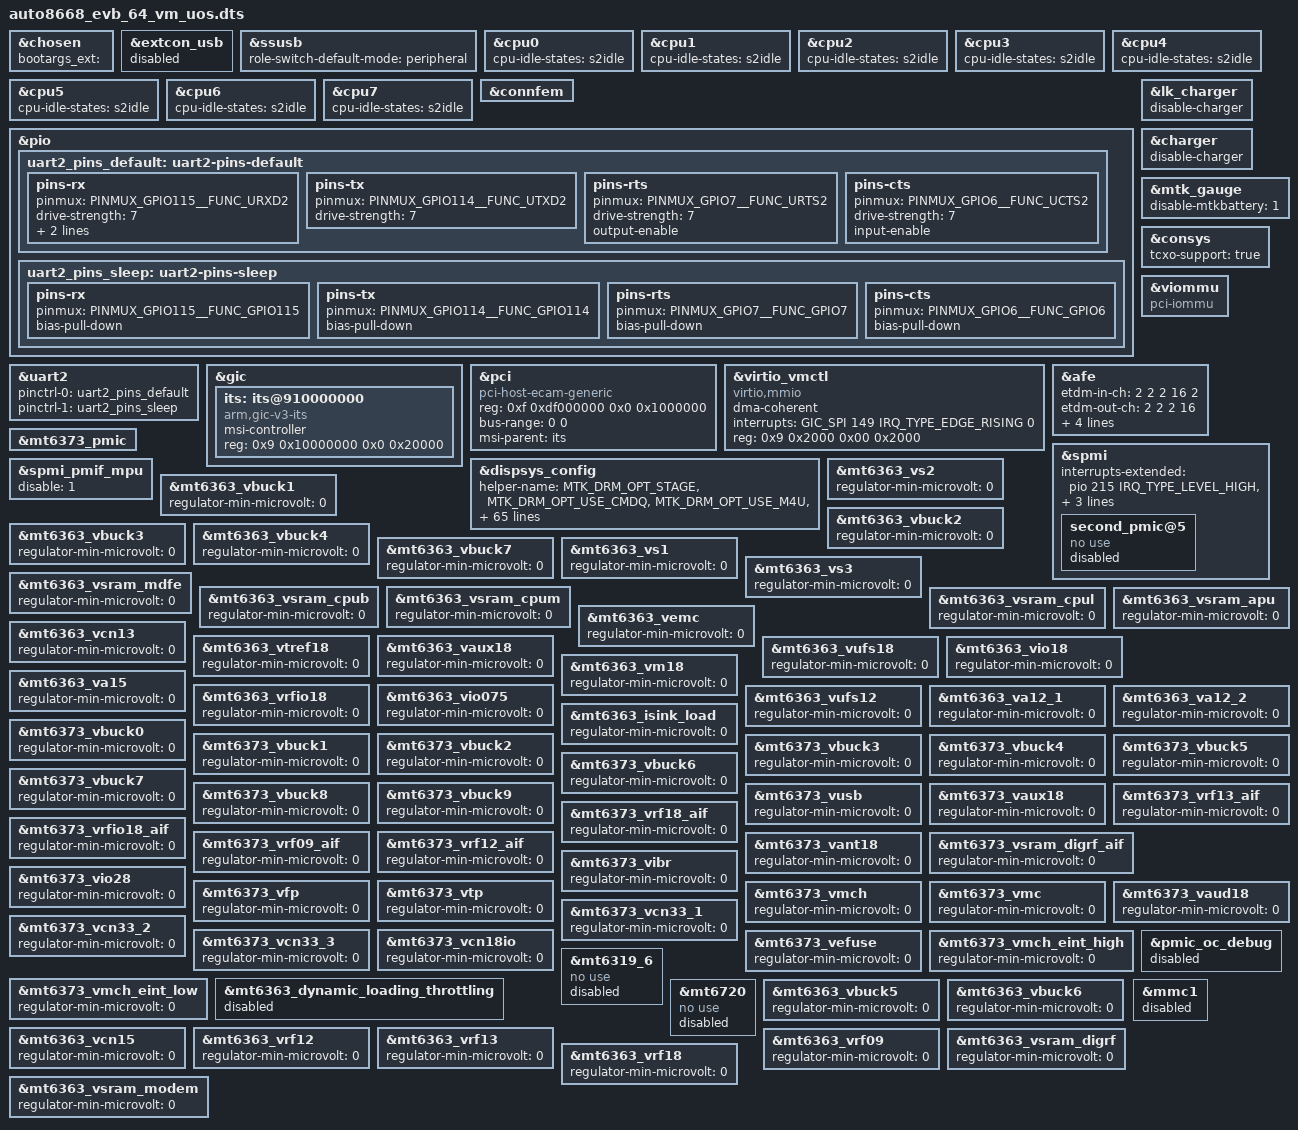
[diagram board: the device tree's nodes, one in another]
// SPDX-License-Identifier: (GPL-2.0 OR MIT)
/*
 * Copyright (c) 2024 MediaTek Inc.
 */

/dts-v1/;
/plugin/;
#include <dt-bindings/interrupt-controller/arm-gic.h>
#include <dt-bindings/interrupt-controller/irq.h>
#include <dt-bindings/pinctrl/mt6881-pinfunc.h>
#include <dt-bindings/phy/phy.h>

/* chosen */
&chosen {
	bootargs_ext = "";
};

&extcon_usb{
	status = "disabled";
};

&ssusb {
	vusb33-supply = <&mt6373_vusb>;
	role-switch-default-mode = "peripheral";
};

&cpu0 {
	cpu-idle-states = <&s2idle>;
};

&cpu1 {
	cpu-idle-states = <&s2idle>;
};

&cpu2 {
	cpu-idle-states = <&s2idle>;
};

&cpu3 {
	cpu-idle-states = <&s2idle>;
};

&cpu4 {
	cpu-idle-states = <&s2idle>;
};

&cpu5 {
	cpu-idle-states = <&s2idle>;
};

&cpu6 {
	cpu-idle-states = <&s2idle>;
};

&cpu7 {
	cpu-idle-states = <&s2idle>;
};

&extcon_usb{
	status = "disabled";
};

&ssusb {
	/delete-property/ vusb33-supply;
	/delete-node/ port;
};

&connfem {
/* Enable epa_elna node to support Wifi & BT ePA/eLNA FEM on customer load */
#if 0
	epa-elna {
		parts = <&wlan7207h &wlan7207c>;
		wifi {
			flags-0 {
				open-loop;
			};
		};
		bt {
			flags-0 {
				/* choose one of: epa-elna/epa/elna/bypass */
				epa-elna;
			};
		};
	};
#endif
};

&pio {
	uart2_pins_default: uart2-pins-default {
		pins-rx {
			pinmux = <PINMUX_GPIO115__FUNC_URXD2>;
			drive-strength = <7>;
			input-enable;
			bias-pull-up;
		};
		pins-tx {
			pinmux = <PINMUX_GPIO114__FUNC_UTXD2>;
			drive-strength = <7>;
		};
		pins-rts {
			pinmux = <PINMUX_GPIO7__FUNC_URTS2>;
			drive-strength = <7>;
			output-enable;
		};
		pins-cts {
			pinmux = <PINMUX_GPIO6__FUNC_UCTS2>;
			drive-strength = <7>;
			input-enable;
		};
	};

	uart2_pins_sleep: uart2-pins-sleep {
		pins-rx {
			pinmux = <PINMUX_GPIO115__FUNC_GPIO115>;
			bias-pull-down;
		};
		pins-tx {
			pinmux = <PINMUX_GPIO114__FUNC_GPIO114>;
			bias-pull-down;
		};
		pins-rts {
			pinmux = <PINMUX_GPIO7__FUNC_GPIO7>;
			bias-pull-down;
		};
		pins-cts {
			pinmux = <PINMUX_GPIO6__FUNC_GPIO6>;
			bias-pull-down;
		};
	};
};


&uart2 {
	pinctrl-names = "default", "sleep";
	pinctrl-0 = <&uart2_pins_default>;
	pinctrl-1 = <&uart2_pins_sleep>;
	status = "okay";
};

&lk_charger {
	disable-charger;
};

&charger {
	disable-charger;
};

&mtk_gauge {
	disable-mtkbattery = <1>;
};

/* CONNSYS TCXO GPIO start */
&consys {
	tcxo-support = "true";
};

&gic {
	ranges;
	its: its@910000000 {
		compatible = "arm,gic-v3-its";
		msi-controller;
		reg = <0x9 0x10000000 0x0 0x20000>;
	};
};

// virtio-pci bus is used to enumerate virtio devices
&pci {
	device_type = "pci";
	compatible = "pci-host-ecam-generic";
	status = "okay";
	reg = <0xf 0xdf000000 0x0 0x1000000>;
	bus-range = <0 0>;
	ranges = <0x2000000 0x0 0xe0001000 0xf 0xe0001000 0x0 0xffff000>;
	#address-cells = <3>;
	#size-cells = <2>;
	#interrupt-cells = <1>;
	msi-parent = <&its>;
};

&virtio_vmctl {
	dma-coherent;
	status = "okay";
	/* must be in sync with mmio irq in uos_alps_pv8678.lua */
	interrupts = <GIC_SPI 149 IRQ_TYPE_EDGE_RISING 0>;
	reg = <0x9 0x2000 0x00 0x2000>;
	compatible = "virtio,mmio";
};

&viommu {
	compatible = "pci-iommu";
	#iommu-cells = <1>;
	status = "okay";
};

&afe {
	etdm-in-ch = <2 2 2 16 2>;
	etdm-out-ch = <2 2 2 16>;
	etdm-in-format = <0 0 0 4 0>;
	etdm-out-format = <0 0 0 4>;
	etdmin6-clk-always-on = <0xf 0xbb80 0x80 0x20 0x10>;/* ao_level, lrck, mclk_ratio, bck_width, channels */
};

&dispsys_config {
	helper-name = "MTK_DRM_OPT_STAGE",
		"MTK_DRM_OPT_USE_CMDQ",
		"MTK_DRM_OPT_USE_M4U",
		"MTK_DRM_OPT_MMQOS_SUPPORT",
		"MTK_DRM_OPT_MMDVFS_SUPPORT",
		"MTK_DRM_OPT_SODI_SUPPORT",
		"MTK_DRM_OPT_IDLE_MGR",
		"MTK_DRM_OPT_IDLEMGR_SWTCH_DECOUPLE",
		"MTK_DRM_OPT_IDLEMGR_BY_REPAINT",
		"MTK_DRM_OPT_IDLEMGR_ENTER_ULPS",
		"MTK_DRM_OPT_IDLEMGR_KEEP_LP11",
		"MTK_DRM_OPT_DYNAMIC_RDMA_GOLDEN_SETTING",
		"MTK_DRM_OPT_IDLEMGR_DISABLE_ROUTINE_IRQ",
		"MTK_DRM_OPT_IDLEMGR_ASYNC",
		"MTK_DRM_OPT_MET_LOG",
		"MTK_DRM_OPT_USE_PQ",
		"MTK_DRM_OPT_ESD_CHECK_RECOVERY",
		"MTK_DRM_OPT_ESD_CHECK_SWITCH",
		"MTK_DRM_OPT_PRESENT_FENCE",
		"MTK_DRM_OPT_RDMA_UNDERFLOW_AEE",
		"MTK_DRM_OPT_DSI_UNDERRUN_AEE",
		"MTK_DRM_OPT_ODDMR_OD_AEE",
		"MTK_DRM_OPT_ODDMR_DMR_AEE",
		"MTK_DRM_OPT_HRT",
		"MTK_DRM_OPT_HRT_MODE",
		"MTK_DRM_OPT_DELAYED_TRIGGER",
		"MTK_DRM_OPT_OVL_EXT_LAYER",
		"MTK_DRM_OPT_AOD",
		"MTK_DRM_OPT_RPO",
		"MTK_DRM_OPT_DUAL_PIPE",
		"MTK_DRM_OPT_DC_BY_HRT",
		"MTK_DRM_OPT_OVL_WCG",
		"MTK_DRM_OPT_OVL_SBCH",
		"MTK_DRM_OPT_COMMIT_NO_WAIT_VBLANK",
		"MTK_DRM_OPT_MET",
		"MTK_DRM_OPT_REG_PARSER_RAW_DUMP",
		"MTK_DRM_OPT_VP_PQ",
		"MTK_DRM_OPT_GAME_PQ",
		"MTK_DRM_OPT_MMPATH",
		"MTK_DRM_OPT_HBM",
		"MTK_DRM_OPT_VDS_PATH_SWITCH",
		"MTK_DRM_OPT_LAYER_REC",
		"MTK_DRM_OPT_CLEAR_LAYER",
		"MTK_DRM_OPT_LFR",
		"MTK_DRM_OPT_SF_PF",
		"MTK_DRM_OPT_DYN_MIPI_CHANGE",
		"MTK_DRM_OPT_PRIM_DUAL_PIPE",
		"MTK_DRM_OPT_MSYNC2_0",
		"MTK_DRM_OPT_MML_PRIMARY",
		"MTK_DRM_OPT_MML_SUPPORT_CMD_MODE",
		"MTK_DRM_OPT_MML_PQ",
		"MTK_DRM_OPT_MML_IR",
		"MTK_DRM_OPT_DUAL_TE",
		"MTK_DRM_OPT_RES_SWITCH",
		"MTK_DRM_OPT_PREFETCH_TE",
		"MTK_DRM_OPT_DPC_EN",
		"MTK_DRM_OPT_VIDLE_TOP_EN",
		"MTK_DRM_OPT_VIDLE_APSRC_OFF",
		"MTK_DRM_OPT_VIDLE_DSI_PLL_OFF",
		"MTK_DRM_OPT_VIDLE_VDO_PANEL",
		"MTK_DRM_OPT_VIDLE_HOME_SCREEN_IDLE",
		"MTK_DRM_OPT_VIDLE_FULL_SCENARIO",
		"MTK_DRM_OPT_DPC_PRE_TE_EN",
		"MTK_DRM_OPT_MMDVFS_MODE_SWITCH",
		"MTK_DRM_OPT_CHECK_TRIGGER_MERGE",
		"MTK_DRM_OPT_VIRTUAL_DISP",
		"MTK_DRM_OPT_OVL_BW_MONITOR",
		"MTK_DRM_OPT_GPU_CACHE",
		"MTK_DRM_OPT_SPHRT",
		"MTK_DRM_OPT_SDPA_OVL_SWITCH",
		"MTK_DRM_OPT_HRT_BY_LARB",
		"MTK_DRM_OPT_MAX_CHANNEL_HRT",
		"MTK_DRM_OPT_RES_SWITCH_ON_AP",
		"MTK_DRM_OPT_TILE_OVERHEAD";

	helper-value = <0>, /*MTK_DRM_OPT_STAGE*/
		<1>, /*MTK_DRM_OPT_USE_CMDQ*/
		<1>, /*MTK_DRM_OPT_USE_M4U*/
		<0>, /*MTK_DRM_OPT_MMQOS_SUPPORT*/
		<0>, /*MTK_DRM_OPT_MMDVFS_SUPPORT*/
		<0>, /*MTK_DRM_OPT_SODI_SUPPORT*/
		<0>, /*MTK_DRM_OPT_IDLE_MGR*/
		<0>, /*MTK_DRM_OPT_IDLEMGR_SWTCH_DECOUPLE*/
		<0>, /*MTK_DRM_OPT_IDLEMGR_BY_REPAINT*/
		<0>, /*MTK_DRM_OPT_IDLEMGR_ENTER_ULPS*/
		<0>, /*MTK_DRM_OPT_IDLEMGR_KEEP_LP11*/
		<0>, /*MTK_DRM_OPT_DYNAMIC_RDMA_GOLDEN_SETTING*/
		<0>, /*MTK_DRM_OPT_IDLEMGR_DISABLE_ROUTINE_IRQ*/
		<0>, /*MTK_DRM_OPT_IDLEMGR_ASYNC*/
		<0>, /*MTK_DRM_OPT_MET_LOG*/
		<0>, /*MTK_DRM_OPT_USE_PQ*/
		<0>, /*MTK_DRM_OPT_ESD_CHECK_RECOVERY*/
		<0>, /*MTK_DRM_OPT_ESD_CHECK_SWITCH*/
		<1>, /*MTK_DRM_OPT_PRESENT_FENCE*/
		<0>, /*MTK_DRM_OPT_RDMA_UNDERFLOW_AEE*/
		<0>, /*MTK_DRM_OPT_DSI_UNDERRUN_AEE*/
		<0>, /*MTK_DRM_OPT_ODDMR_OD_AEE*/
		<0>, /*MTK_DRM_OPT_ODDMR_DMR_AEE*/
		<1>, /*MTK_DRM_OPT_HRT*/
		<0>, /*MTK_DRM_OPT_HRT_MODE*/
		<0>, /*MTK_DRM_OPT_DELAYED_TRIGGER*/
		<1>, /*MTK_DRM_OPT_OVL_EXT_LAYER*/
		<0>, /*MTK_DRM_OPT_AOD*/
		<0>, /*MTK_DRM_OPT_RPO*/
		<0>, /*MTK_DRM_OPT_DUAL_PIPE*/
		<0>, /*MTK_DRM_OPT_DC_BY_HRT*/
		<0>, /*MTK_DRM_OPT_OVL_WCG*/
		<0>, /*MTK_DRM_OPT_OVL_SBCH*/
		<1>, /*MTK_DRM_OPT_COMMIT_NO_WAIT_VBLANK*/
		<0>, /*MTK_DRM_OPT_MET*/
		<0>, /*MTK_DRM_OPT_REG_PARSER_RAW_DUMP*/
		<0>, /*MTK_DRM_OPT_VP_PQ*/
		<0>, /*MTK_DRM_OPT_GAME_PQ*/
		<0>, /*MTK_DRM_OPT_MMPATH*/
		<0>, /*MTK_DRM_OPT_HBM*/
		<0>, /*MTK_DRM_OPT_VDS_PATH_SWITCH*/
		<0>, /*MTK_DRM_OPT_LAYER_REC*/
		<1>, /*MTK_DRM_OPT_CLEAR_LAYER*/
		<0>, /*MTK_DRM_OPT_LFR*/
		<0>, /*MTK_DRM_OPT_SF_PF*/
		<1>, /*MTK_DRM_OPT_DYN_MIPI_CHANGE*/
		<0>, /*MTK_DRM_OPT_PRIM_DUAL_PIPE*/
		<0>, /*MTK_DRM_OPT_MSYNC2_0*/
		<0>, /*MTK_DRM_OPT_MML_PRIMARY*/
		<0>, /*MTK_DRM_OPT_MML_SUPPORT_CMD_MODE*/
		<0>, /*MTK_DRM_OPT_MML_PQ*/
		<0>, /*MTK_DRM_OPT_MML_IR*/
		<0>, /*MTK_DRM_OPT_DUAL_TE*/
		<0>, /*MTK_DRM_OPT_RES_SWITCH*/
		<0>, /*MTK_DRM_OPT_PREFETCH_TE*/
		<1>, /*MTK_DRM_OPT_DPC_EN*/
		<0>, /*MTK_DRM_OPT_VIDLE_TOP_EN*/
		<0>, /*MTK_DRM_OPT_VIDLE_APSRC_OFF*/
		<0>, /*MTK_DRM_OPT_VIDLE_DSI_PLL_OFF*/
		<0>, /*MTK_DRM_OPT_VIDLE_VDO_PANEL*/
		<0>, /*MTK_DRM_OPT_VIDLE_HOME_SCREEN_IDLE*/
		<0>, /*MTK_DRM_OPT_VIDLE_FULL_SCENARIO*/
		<0>, /*MTK_DRM_OPT_DPC_PRE_TE_EN*/
		<0>, /*MTK_DRM_OPT_MMDVFS_MODE_SWITCH*/
		<0>, /*MTK_DRM_OPT_CHECK_TRIGGER_MERGE*/
		<0>, /*MTK_DRM_OPT_VIRTUAL_DISP*/
		<1>, /*MTK_DRM_OPT_OVL_BW_MONITOR*/
		<0>, /*MTK_DRM_OPT_GPU_CACHE*/
		<1>, /*MTK_DRM_OPT_SPHRT*/
		<1>, /*MTK_DRM_OPT_SDPA_OVL_SWITCH*/
		<0>, /*MTK_DRM_OPT_HRT_BY_LARB*/
		<0>, /*MTK_DRM_OPT_MAX_CHANNEL_HRT*/
		<0>, /*MTK_DRM_OPT_RES_SWITCH_ON_AP*/
		<0>; /*MTK_DRM_OPT_TILE_OVERHEAD*/

	status = "okay";
};

&spmi {
	interrupts-extended = <&pio 215 IRQ_TYPE_LEVEL_HIGH>,
			<&gic GIC_SPI 624 IRQ_TYPE_LEVEL_HIGH 0>,
			<&gic GIC_SPI 642 IRQ_TYPE_LEVEL_HIGH 0>;
	interrupt-names = "rcs_irq",
			"pmif_irq","spmi_nack_irq";
	spmi-dev-mask = <0x0>;
};

&mt6373_pmic {
	status = "okay";
};

&spmi_pmif_mpu {
	disable = <1>;
};

&mt6363_vs2 {
	regulator-min-microvolt = <0>;
};

&mt6363_vbuck1 {
	regulator-min-microvolt = <0>;
};

&mt6363_vbuck2 {
	regulator-min-microvolt = <0>;
};

&mt6363_vbuck3 {
	regulator-min-microvolt = <0>;
};

&mt6363_vbuck4 {
	regulator-min-microvolt = <0>;
};

&mt6363_vbuck7 {
	regulator-min-microvolt = <0>;
};

&mt6363_vs1 {
	regulator-min-microvolt = <0>;
};

&mt6363_vs3 {
	regulator-min-microvolt = <0>;
};

&mt6363_vsram_mdfe {
	regulator-min-microvolt = <0>;
};

&mt6363_vsram_cpub {
	regulator-min-microvolt = <0>;
};

&mt6363_vsram_cpum {
	regulator-min-microvolt = <0>;
};

&mt6363_vsram_cpul {
	regulator-min-microvolt = <0>;
};

&mt6363_vsram_apu {
	regulator-min-microvolt = <0>;
};

&mt6363_vemc {
	regulator-min-microvolt = <0>;
};

&mt6363_vcn13 {
	regulator-min-microvolt = <0>;
};

&mt6363_vtref18 {
	regulator-min-microvolt = <0>;
};

&mt6363_vaux18 {
	regulator-min-microvolt = <0>;
};

&mt6363_vufs18 {
	regulator-min-microvolt = <0>;
};

&mt6363_vio18 {
	regulator-min-microvolt = <0>;
};

&mt6363_vm18 {
	regulator-min-microvolt = <0>;
};

&mt6363_va15 {
	regulator-min-microvolt = <0>;
};

&mt6363_vrfio18 {
	regulator-min-microvolt = <0>;
};

&mt6363_vio075 {
	regulator-min-microvolt = <0>;
};

&mt6363_vufs12 {
	regulator-min-microvolt = <0>;
};

&mt6363_va12_1 {
	regulator-min-microvolt = <0>;
};

&mt6363_va12_2 {
	regulator-min-microvolt = <0>;
};

&mt6363_isink_load {
	regulator-min-microvolt = <0>;
};

&mt6373_vbuck0 {
	regulator-min-microvolt = <0>;
};

&mt6373_vbuck1 {
	regulator-min-microvolt = <0>;
};

&mt6373_vbuck2 {
	regulator-min-microvolt = <0>;
};

&mt6373_vbuck3 {
	regulator-min-microvolt = <0>;
};

&mt6373_vbuck4 {
	regulator-min-microvolt = <0>;
};

&mt6373_vbuck5 {
	regulator-min-microvolt = <0>;
};

&mt6373_vbuck6 {
	regulator-min-microvolt = <0>;
};

&mt6373_vbuck7 {
	regulator-min-microvolt = <0>;
};

&mt6373_vbuck8 {
	regulator-min-microvolt = <0>;
};

&mt6373_vbuck9 {
	regulator-min-microvolt = <0>;
};

&mt6373_vusb {
	regulator-min-microvolt = <0>;
};

&mt6373_vaux18 {
	regulator-min-microvolt = <0>;
};

&mt6373_vrf13_aif {
	regulator-min-microvolt = <0>;
};

&mt6373_vrf18_aif {
	regulator-min-microvolt = <0>;
};

&mt6373_vrfio18_aif {
	regulator-min-microvolt = <0>;
};

&mt6373_vrf09_aif {
	regulator-min-microvolt = <0>;
};

&mt6373_vrf12_aif {
	regulator-min-microvolt = <0>;
};

&mt6373_vant18 {
	regulator-min-microvolt = <0>;
};

&mt6373_vsram_digrf_aif {
	regulator-min-microvolt = <0>;
};

&mt6373_vibr {
	regulator-min-microvolt = <0>;
};

&mt6373_vio28 {
	regulator-min-microvolt = <0>;
};

&mt6373_vfp {
	regulator-min-microvolt = <0>;
};

&mt6373_vtp {
	regulator-min-microvolt = <0>;
};

&mt6373_vmch {
	regulator-min-microvolt = <0>;
};

&mt6373_vmc {
	regulator-min-microvolt = <0>;
};

&mt6373_vaud18 {
	regulator-min-microvolt = <0>;
};

&mt6373_vcn33_1 {
	regulator-min-microvolt = <0>;
};

&mt6373_vcn33_2 {
	regulator-min-microvolt = <0>;
};

&mt6373_vcn33_3 {
	regulator-min-microvolt = <0>;
};

&mt6373_vcn18io {
	regulator-min-microvolt = <0>;
};

&mt6373_vefuse {
	regulator-min-microvolt = <0>;
};

&mt6373_vmch_eint_high {
	regulator-min-microvolt = <0>;
};

&mt6373_vmch_eint_low {
	regulator-min-microvolt = <0>;
};

&pmic_oc_debug {
	status = "disabled";
};

&mt6363_dynamic_loading_throttling {
	status = "disabled";
};

&mt6319_6 {
	compatible = "no use";
	status = "disabled";
};

&mt6720 {
	compatible = "no use";
	status = "disabled";
};

&spmi {
	second_pmic@5 {
		compatible = "no use";
		status = "disabled";
	};
};

/* MD/RF always-on setting */
&mt6363_vbuck5 {
	regulator-min-microvolt = <0>;
};

&mt6363_vbuck6 {
	regulator-min-microvolt = <0>;
};

&mt6363_vcn15 {
	regulator-min-microvolt = <0>;
};

&mt6363_vrf12 {
	regulator-min-microvolt = <0>;
};

&mt6363_vrf13 {
	regulator-min-microvolt = <0>;
};

&mt6363_vrf09 {
	regulator-min-microvolt = <0>;
};

&mt6363_vsram_digrf {
	regulator-min-microvolt = <0>;
};

&mt6363_vsram_modem {
	regulator-min-microvolt = <0>;
};

&mt6363_vrf18 {
	regulator-min-microvolt = <0>;
};

&mmc1 {
	status = "disabled";
};

#include <auto8668p1_64_vm_uos/cust.dtsi>
#include "mediatek/cust_mt8668_display_interface_EVB.dtsi"
#include "mediatek/cust_mt8668_display_serdes_config.dtsi"
#include "mediatek/cust_mt8668_display_config_main.dtsi"
#include "mediatek/cust_k6881_connfem.dtsi"
/*End of this file, DO NOT ADD ANYTHING HERE*/
